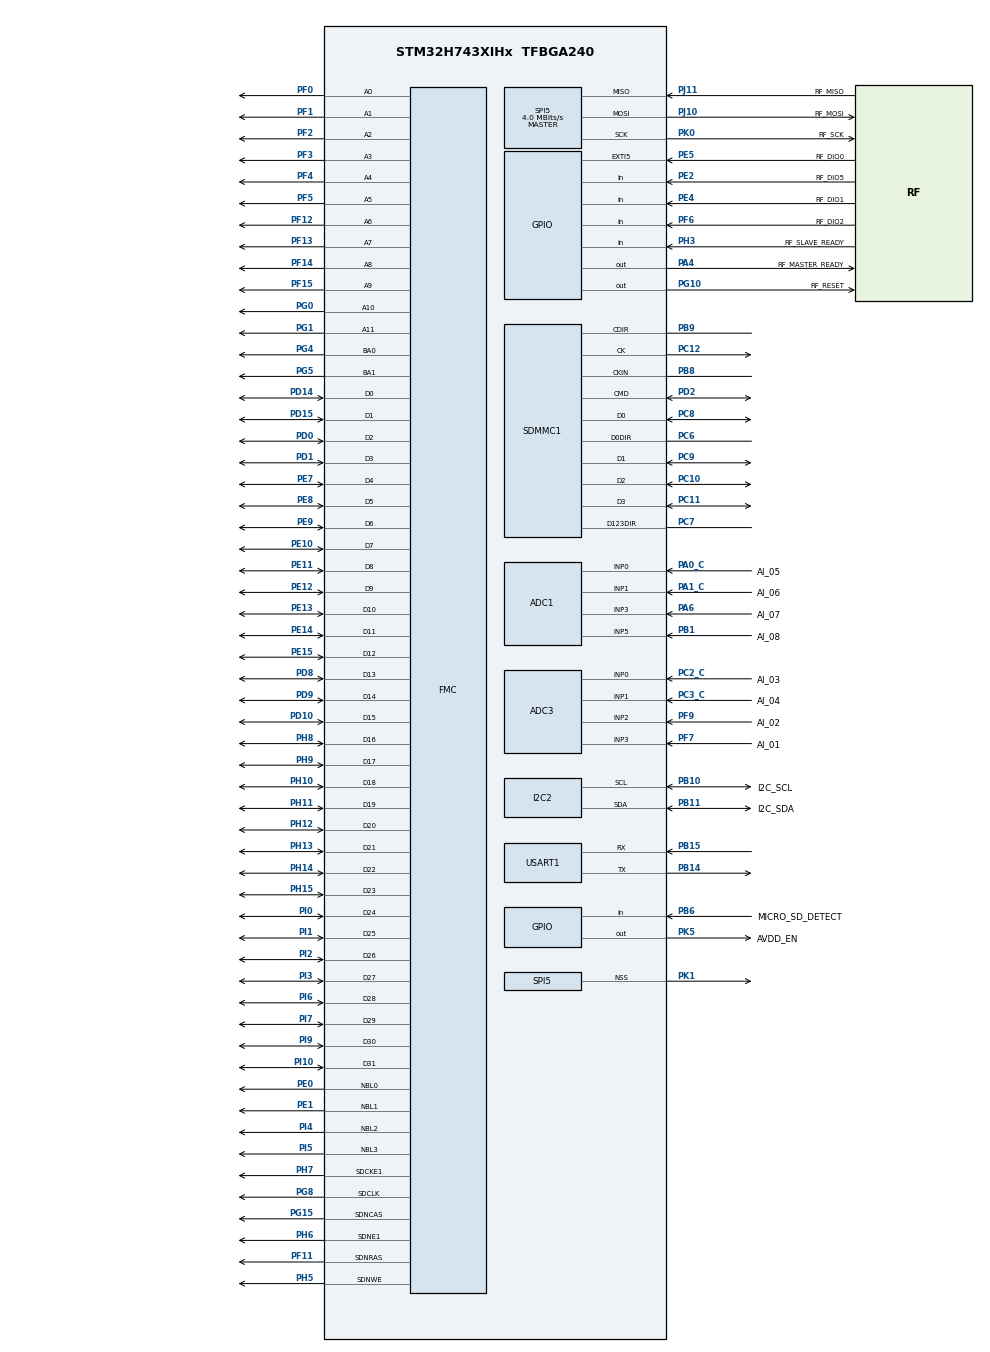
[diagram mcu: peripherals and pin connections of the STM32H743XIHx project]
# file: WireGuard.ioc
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ADC1.Channel-0\#ChannelRegularConversion=ADC_CHANNEL_0
ADC1.ClockPrescaler=ADC_CLOCK_ASYNC_DIV2
ADC1.ContinuousConvMode=ENABLE
ADC1.NbrOfConversionFlag=1
ADC1.OffsetNumber-0\#ChannelRegularConversion=ADC_OFFSET_NONE
ADC1.Rank-0\#ChannelRegularConversion=1
ADC1.SamplingTime-0\#ChannelRegularConversion=ADC_SAMPLETIME_1CYCLE_5
ADC1.master=1
ADC3.Channel-0\#ChannelRegularConversion=ADC_CHANNEL_0
ADC3.ContinuousConvMode=ENABLE
ADC3.LowPowerAutoWait=DISABLE
ADC3.NbrOfConversionFlag=1
ADC3.OffsetNumber-0\#ChannelRegularConversion=ADC_OFFSET_NONE
ADC3.Rank-0\#ChannelRegularConversion=1
ADC3.SamplingTime-0\#ChannelRegularConversion=ADC_SAMPLETIME_1CYCLE_5
FATFS.BSP.number=1
FATFS0.BSP.STBoard=false
FATFS0.BSP.api=Unknown
FATFS0.BSP.i2caddr=0
FATFS0.BSP.instance=PB6
FATFS0.BSP.ip=GPIO
FATFS0.BSP.mode=Input
FATFS0.BSP.name=Detect_SDIO
FATFS0.BSP.solution=PB6
FMC.CASLatency1=FMC_SDRAM_CAS_LATENCY_3
FMC.ColumnBitsNumber1=FMC_SDRAM_COLUMN_BITS_NUM_9
FMC.ExitSelfRefreshDelay1=7
FMC.LoadToActiveDelay1=2
FMC.RCDDelay1=2
FMC.RPDelay1=2
FMC.RPDelay2=2
FMC.ReadBurst1=FMC_SDRAM_RBURST_ENABLE
FMC.ReadBurst2=FMC_SDRAM_RBURST_ENABLE
FMC.RowCycleDelay1=7
FMC.RowCycleDelay2=7
FMC.SDClockPeriod1=FMC_SDRAM_CLOCK_PERIOD_2
FMC.SelfRefreshTime1=4
FMC.WriteRecoveryTime1=4
FREERTOS.HEAP_NUMBER=4
FREERTOS.Tasks01=defaultTask,0,512,MAIN_taskEntry,As weak,NULL,Dynamic,NULL,NULL
FREERTOS.Timers01=timerSystemMonitor,SYSTEM_montiorCallback,osTimerPeriodic,As weak,NULL,Dynamic,NULL
FREERTOS.configCHECK_FOR_STACK_OVERFLOW=1
FREERTOS.configMINIMAL_STACK_SIZE=256
FREERTOS.configTOTAL_HEAP_SIZE=32768
FREERTOS.configUSE_TIMERS=1
I2C2.Timing=0x10909CEC
Mcu.Family=STM32H7
Mcu.Name=STM32H743XIHx
Mcu.Package=TFBGA240
NVIC.ADC3_IRQn=true\:5\:0\:false\:false\:true\:true\:true\:true
NVIC.ADC_IRQn=true\:5\:0\:false\:false\:true\:true\:true\:true
NVIC.EXTI9_5_IRQn=true\:5\:0\:false\:false\:true\:true\:true\:true
NVIC.PriorityGroup=NVIC_PRIORITYGROUP_4
NVIC.SPI5_IRQn=true\:5\:0\:false\:false\:true\:true\:true\:true
NVIC.TIM1_UP_IRQn=true\:0\:0\:false\:false\:true\:false\:false\:false
NVIC.TimeBase=TIM1_UP_IRQn
NVIC.TimeBaseIP=TIM1
PA0_C.GPIO_Label=AI_05
PA0_C.Signal=ADCx_INP0
PA13\ (JTMS/SWDIO).Mode=JTAG_5_pins
PA13\ (JTMS/SWDIO).Signal=SYS_JTMS-SWDIO
PA14\ (JTCK/SWCLK).Mode=JTAG_5_pins
PA14\ (JTCK/SWCLK).Signal=SYS_JTCK-SWCLK
PA15\ (JTDI).Mode=JTAG_5_pins
PA15\ (JTDI).Signal=SYS_JTDI
PA1_C.GPIO_Label=AI_06
PA1_C.Signal=ADCx_INP1
PA4.GPIO_Label=RF_MASTER_READY
PA4.GPIO_PuPd=GPIO_PULLUP
PA4.GPIO_Speed=GPIO_SPEED_FREQ_VERY_HIGH
PA4.Signal=GPIO_Output
PA6.GPIO_Label=AI_07
PA6.Signal=ADCx_INP3
PB1.GPIO_Label=AI_08
PB1.Signal=ADCx_INP5
PB10.GPIO_Label=I2C_SCL
PB10.GPIO_PuPd=GPIO_PULLUP
PB10.Mode=I2C
PB10.Signal=I2C2_SCL
PB11.GPIO_Label=I2C_SDA
PB11.GPIO_PuPd=GPIO_PULLUP
PB11.Mode=I2C
PB11.Signal=I2C2_SDA
PB14.Mode=Asynchronous
PB14.Signal=USART1_TX
PB15.Mode=Asynchronous
PB15.Signal=USART1_RX
PB3\ (JTDO/TRACESWO).Mode=JTAG_5_pins
PB3\ (JTDO/TRACESWO).Signal=SYS_JTDO-SWO
PB4\ (NJTRST).Mode=JTAG_5_pins
PB4\ (NJTRST).Signal=SYS_JTRST
PB6.GPIO_Label=MICRO_SD_DETECT
PB6.Signal=GPIO_Input
PB8.Mode=SD_4_bits_Wide_bus_dir_voltage_converter
PB8.Signal=SDMMC1_CKIN
PB9.Mode=SD_4_bits_Wide_bus_dir_voltage_converter
PB9.Signal=SDMMC1_CDIR
PC10.Mode=SD_4_bits_Wide_bus_dir_voltage_converter
PC10.Signal=SDMMC1_D2
PC11.Mode=SD_4_bits_Wide_bus_dir_voltage_converter
PC11.Signal=SDMMC1_D3
PC12.Mode=SD_4_bits_Wide_bus_dir_voltage_converter
PC12.Signal=SDMMC1_CK
PC14-OSC32_IN\ (OSC32_IN).Mode=LSE-External-Oscillator
PC14-OSC32_IN\ (OSC32_IN).Signal=RCC_OSC32_IN
PC15-OSC32_OUT\ (OSC32_OUT).Mode=LSE-External-Oscillator
PC15-OSC32_OUT\ (OSC32_OUT).Signal=RCC_OSC32_OUT
PC2_C.GPIO_Label=AI_03
PC2_C.Mode=IN0-Single-Ended
PC2_C.Signal=ADC3_INP0
PC3_C.GPIO_Label=AI_04
PC3_C.Mode=IN1-Single-Ended
PC3_C.Signal=ADC3_INP1
PC6.Mode=SD_4_bits_Wide_bus_dir_voltage_converter
PC6.Signal=SDMMC1_D0DIR
PC7.Mode=SD_4_bits_Wide_bus_dir_voltage_converter
PC7.Signal=SDMMC1_D123DIR
PC8.Mode=SD_4_bits_Wide_bus_dir_voltage_converter
PC8.Signal=SDMMC1_D0
PC9.Mode=SD_4_bits_Wide_bus_dir_voltage_converter
PC9.Signal=SDMMC1_D1
PD0.Signal=FMC_D2_DA2
PD1.Signal=FMC_D3_DA3
PD10.Signal=FMC_D15_DA15
PD14.Signal=FMC_D0_DA0
PD15.Signal=FMC_D1_DA1
PD2.Mode=SD_4_bits_Wide_bus_dir_voltage_converter
PD2.Signal=SDMMC1_CMD
PD8.Signal=FMC_D13_DA13
PD9.Signal=FMC_D14_DA14
PE0.Signal=FMC_NBL0
PE1.Signal=FMC_NBL1
PE10.Signal=FMC_D7_DA7
PE11.Signal=FMC_D8_DA8
PE12.Signal=FMC_D9_DA9
PE13.Signal=FMC_D10_DA10
PE14.Signal=FMC_D11_DA11
PE15.Signal=FMC_D12_DA12
PE2.GPIO_Label=RF_DIO5
PE2.Signal=GPIO_Input
PE4.GPIO_Label=RF_DIO1
PE4.Signal=GPIO_Input
PE5.GPIO_Label=RF_DIO0
PE5.Signal=GPXTI5
PE7.Signal=FMC_D4_DA4
PE8.Signal=FMC_D5_DA5
PE9.Signal=FMC_D6_DA6
PF0.Signal=FMC_A0
PF1.Signal=FMC_A1
PF11.Signal=FMC_SDNRAS
PF12.Signal=FMC_A6
PF13.Signal=FMC_A7
PF14.Signal=FMC_A8
PF15.Signal=FMC_A9
PF2.Signal=FMC_A2
PF3.Signal=FMC_A3
PF4.Signal=FMC_A4
PF5.Signal=FMC_A5
PF6.GPIO_Label=RF_DIO2
PF6.Signal=GPIO_Input
PF7.GPIO_Label=AI_01
PF7.Mode=IN3-Single-Ended
PF7.Signal=ADC3_INP3
PF9.GPIO_Label=AI_02
PF9.Mode=IN2-Single-Ended
PF9.Signal=ADC3_INP2
PG0.Signal=FMC_A10
PG1.Signal=FMC_A11
PG10.GPIO_Label=RF_RESET
PG10.GPIO_ModeDefaultOutputPP=GPIO_MODE_OUTPUT_OD
PG10.GPIO_PuPd=GPIO_NOPULL
PG10.PinState=GPIO_PIN_RESET
PG10.Signal=GPIO_Output
PG15.Signal=FMC_SDNCAS
PG4.Signal=FMC_A14_BA0
PG5.Signal=FMC_A15_BA1
PG8.Signal=FMC_SDCLK
PH0-OSC_IN\ (PH0).Signal=RCC_OSC_IN
PH1-OSC_OUT\ (PH1).Signal=RCC_OSC_OUT
PH10.Signal=FMC_D18
PH11.Signal=FMC_D19
PH12.Signal=FMC_D20
PH13.Signal=FMC_D21
PH14.Signal=FMC_D22
PH15.Signal=FMC_D23
PH3.GPIO_Label=RF_SLAVE_READY
PH3.GPIO_PuPd=GPIO_PULLUP
PH3.Signal=GPIO_Input
PH5.Signal=FMC_SDNWE
PH6.Mode=SdramChipSelect2_1
PH6.Signal=FMC_SDNE1
PH7.Mode=SdramChipSelect2_1
PH7.Signal=FMC_SDCKE1
PH8.Signal=FMC_D16
PH9.Signal=FMC_D17
PI0.Signal=FMC_D24
PI1.Signal=FMC_D25
PI10.Signal=FMC_D31
PI2.Signal=FMC_D26
PI3.Signal=FMC_D27
PI4.Signal=FMC_NBL2
PI5.Signal=FMC_NBL3
PI6.Signal=FMC_D28
PI7.Signal=FMC_D29
PI9.Signal=FMC_D30
PJ10.GPIO_Label=RF_MOSI
PJ10.Mode=Full_Duplex_Master
PJ10.Signal=SPI5_MOSI
PJ11.GPIO_Label=RF_MISO
PJ11.Mode=Full_Duplex_Master
PJ11.Signal=SPI5_MISO
PK0.GPIO_Label=RF_SCK
PK0.Mode=Full_Duplex_Master
PK0.Signal=SPI5_SCK
PK1.Mode=NSS_Signal_Hard_Output
PK1.Signal=SPI5_NSS
PK5.GPIO_Label=AVDD_EN
PK5.GPIO_PuPd=GPIO_PULLDOWN
PK5.Signal=GPIO_Output
ProjectManager.HeapSize=0x200
ProjectManager.StackSize=0x400
ProjectManager.TargetToolchain=EWARM V8
RCC.ADCCLockSelection=RCC_ADCCLKSOURCE_CLKP
RCC.ADCFreq_Value=64000000
RCC.APB1Freq_Value=80000000
RCC.APB2Freq_Value=20000000
RCC.APB3Freq_Value=80000000
RCC.APB4Freq_Value=80000000
RCC.CortexFreq_Value=80000000
RCC.D2PPRE2=RCC_APB2_DIV4
RCC.DIVM1=4
RCC.DIVM2=4
RCC.DIVN1=10
RCC.DIVN2=10
RCC.DIVP2=1
RCC.HCLKFreq_Value=80000000
RCC.HSE_VALUE=25000000
RCC.PWR_Regulator_Voltage_Scale=PWR_REGULATOR_VOLTAGE_SCALE1
RCC.SYSCLKFreq_VALUE=80000000
RCC.SYSCLKSource=RCC_SYSCLKSOURCE_PLLCLK
RCC.Spi45ClockSelection=RCC_SPI45CLKSOURCE_HSI
RCC.USBFreq_Value=80000000
SH.ADCx_INP0.0=ADC1_INP0,IN0-Single-Ended
SH.ADCx_INP1.0=ADC1_INP1,IN1-Single-Ended
SH.ADCx_INP3.0=ADC1_INP3,IN3-Single-Ended
SH.ADCx_INP5.0=ADC1_INP5,IN5-Single-Ended
SH.FMC_A0.0=FMC_A0,12b-sda1
SH.FMC_A1.0=FMC_A1,12b-sda1
SH.FMC_A10.0=FMC_A10,12b-sda1
SH.FMC_A11.0=FMC_A11,12b-sda1
SH.FMC_A14_BA0.0=FMC_BA0,FourSdramBanks1
SH.FMC_A15_BA1.0=FMC_BA1,FourSdramBanks1
SH.FMC_A2.0=FMC_A2,12b-sda1
SH.FMC_A3.0=FMC_A3,12b-sda1
SH.FMC_A4.0=FMC_A4,12b-sda1
SH.FMC_A5.0=FMC_A5,12b-sda1
SH.FMC_A6.0=FMC_A6,12b-sda1
SH.FMC_A7.0=FMC_A7,12b-sda1
SH.FMC_A8.0=FMC_A8,12b-sda1
SH.FMC_A9.0=FMC_A9,12b-sda1
SH.FMC_D0_DA0.0=FMC_D0,sd-32b-d1
SH.FMC_D10_DA10.0=FMC_D10,sd-32b-d1
SH.FMC_D11_DA11.0=FMC_D11,sd-32b-d1
SH.FMC_D12_DA12.0=FMC_D12,sd-32b-d1
SH.FMC_D13_DA13.0=FMC_D13,sd-32b-d1
SH.FMC_D14_DA14.0=FMC_D14,sd-32b-d1
SH.FMC_D15_DA15.0=FMC_D15,sd-32b-d1
SH.FMC_D16.0=FMC_D16,sd-32b-d1
SH.FMC_D17.0=FMC_D17,sd-32b-d1
SH.FMC_D18.0=FMC_D18,sd-32b-d1
SH.FMC_D19.0=FMC_D19,sd-32b-d1
SH.FMC_D1_DA1.0=FMC_D1,sd-32b-d1
SH.FMC_D20.0=FMC_D20,sd-32b-d1
SH.FMC_D21.0=FMC_D21,sd-32b-d1
SH.FMC_D22.0=FMC_D22,sd-32b-d1
SH.FMC_D23.0=FMC_D23,sd-32b-d1
SH.FMC_D24.0=FMC_D24,sd-32b-d1
SH.FMC_D25.0=FMC_D25,sd-32b-d1
SH.FMC_D26.0=FMC_D26,sd-32b-d1
SH.FMC_D27.0=FMC_D27,sd-32b-d1
SH.FMC_D28.0=FMC_D28,sd-32b-d1
SH.FMC_D29.0=FMC_D29,sd-32b-d1
SH.FMC_D2_DA2.0=FMC_D2,sd-32b-d1
SH.FMC_D30.0=FMC_D30,sd-32b-d1
SH.FMC_D31.0=FMC_D31,sd-32b-d1
SH.FMC_D3_DA3.0=FMC_D3,sd-32b-d1
SH.FMC_D4_DA4.0=FMC_D4,sd-32b-d1
SH.FMC_D5_DA5.0=FMC_D5,sd-32b-d1
SH.FMC_D6_DA6.0=FMC_D6,sd-32b-d1
SH.FMC_D7_DA7.0=FMC_D7,sd-32b-d1
SH.FMC_D8_DA8.0=FMC_D8,sd-32b-d1
SH.FMC_D9_DA9.0=FMC_D9,sd-32b-d1
SH.FMC_NBL0.0=FMC_NBL0,Sd4ByteEnable1
SH.FMC_NBL1.0=FMC_NBL1,Sd4ByteEnable1
SH.FMC_NBL2.0=FMC_NBL2,Sd4ByteEnable1
SH.FMC_NBL3.0=FMC_NBL3,Sd4ByteEnable1
SH.FMC_SDCLK.0=FMC_SDCLK,12b-sda1
SH.FMC_SDNCAS.0=FMC_SDNCAS,12b-sda1
SH.FMC_SDNRAS.0=FMC_SDNRAS,12b-sda1
SH.FMC_SDNWE.0=FMC_SDNWE,12b-sda1
SPI5.BaudRatePrescaler=SPI_BAUDRATEPRESCALER_16
SPI5.CLKPhase=SPI_PHASE_1EDGE
SPI5.CLKPolarity=SPI_POLARITY_LOW
SPI5.CalculateBaudRate=4.0 MBits/s
SPI5.DataSize=SPI_DATASIZE_8BIT
SPI5.Direction=SPI_DIRECTION_2LINES
SPI5.Mode=SPI_MODE_MASTER
SPI5.NSSPMode=SPI_NSS_PULSE_ENABLE
SPI5.RxCRCInitializationPattern=SPI_CRC_INITIALIZATION_ALL_ZERO_PATTERN
SPI5.TxCRCInitializationPattern=SPI_CRC_INITIALIZATION_ALL_ZERO_PATTERN
SPI5.VirtualNSS=VM_NSSHARD
SPI5.VirtualType=VM_MASTER
USART1.VirtualMode-Asynchronous=VM_ASYNC
VP_FATFS_VS_SDIO.Mode=SDIO
VP_FREERTOS_VS_CMSIS_V1.Mode=CMSIS_V1
VP_RTC_VS_RTC_Activate.Mode=RTC_Enabled
VP_SYS_VS_tim1.Mode=TIM1
board=custom

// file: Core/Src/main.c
/* USER CODE BEGIN Header */
/**
  ******************************************************************************
  * @file           : main.c
  * @brief          : Main program body
  ******************************************************************************
  * @attention
  *
  * <h2><center>&copy; Copyright (c) 2019 STMicroelectronics.
  * All rights reserved.</center></h2>
  *
  * This software component is licensed by ST under Ultimate Liberty license
  * SLA0044, the "License"; You may not use this file except in compliance with
  * the License. You may obtain a copy of the License at:
  *                             www.st.com/SLA0044
  *
  ******************************************************************************
  */
/* USER CODE END Header */

#include "main.h"
#include "cmsis_os.h"
#include "fatfs.h"

/* USER CODE BEGIN Includes */
#include "sdram.h"
#include "adc.h"
#include "rf.h"
#include "i2c.h"
#include "wireguard.h"
/* USER CODE END Includes */

ADC_HandleTypeDef hadc1;
ADC_HandleTypeDef hadc3;

I2C_HandleTypeDef hi2c2;

RTC_HandleTypeDef hrtc;

SD_HandleTypeDef hsd1;

SPI_HandleTypeDef hspi5;

UART_HandleTypeDef huart1;

SDRAM_HandleTypeDef hsdram1;

osThreadId defaultTaskHandle;
osTimerId timerSystemMonitorHandle;
/* USER CODE BEGIN PV */
/* Private variables ---------------------------------------------------------*/
ADC_HandleTypeDef*  adcList[] = {&hadc1, &hadc3};

/* USER CODE END PV */

void SystemClock_Config(void);
static void MX_GPIO_Init(void);
static void MX_ADC1_Init(void);
static void MX_ADC3_Init(void);
static void MX_FMC_Init(void);
static void MX_SDMMC1_SD_Init(void);
static void MX_USART1_UART_Init(void);
static void MX_SPI5_Init(void);
static void MX_RTC_Init(void);
static void MX_I2C2_Init(void);
void MAIN_taskEntry(void const * argument);
void SYSTEM_montiorCallback(void const * argument);

/* USER CODE BEGIN PFP */
/* Private function prototypes -----------------------------------------------*/

/* USER CODE END PFP */

int main(void)
{

  /* MCU Configuration--------------------------------------------------------*/

  /* Reset of all peripherals, Initializes the Flash interface and the Systick. */
  HAL_Init();

  /* Configure the system clock */
  SystemClock_Config();

  /* Initialize all configured peripherals */
  MX_GPIO_Init();
  MX_ADC1_Init();
  MX_ADC3_Init();
  MX_FMC_Init();
  MX_SDMMC1_SD_Init();
  MX_USART1_UART_Init();
  MX_SPI5_Init();
  MX_RTC_Init();
  MX_I2C2_Init();
  /* USER CODE BEGIN 2 */
  ADC_init(adcList, 2);
  SDRAM_init(&hsdram1);
  RF_init(&hspi5);
  I2C_init(&hi2c2);

  /* USER CODE END 2 */

  /* Create the timer(s) */
  /* definition and creation of timerSystemMonitor */
  osTimerDef(timerSystemMonitor, SYSTEM_montiorCallback);
  timerSystemMonitorHandle = osTimerCreate(osTimer(timerSystemMonitor), osTimerPeriodic, NULL);

  /* Create the thread(s) */
  /* definition and creation of defaultTask */
  osThreadDef(defaultTask, MAIN_taskEntry, osPriorityNormal, 0, 512);
  defaultTaskHandle = osThreadCreate(osThread(defaultTask), NULL);

  /* Start scheduler */
  osKernelStart();

  /* We should never get here as control is now taken by the scheduler */

  /* Infinite loop */
  while (1)
  {

  }
}

void SystemClock_Config(void)
{
  RCC_OscInitTypeDef RCC_OscInitStruct = {0};
  RCC_ClkInitTypeDef RCC_ClkInitStruct = {0};
  RCC_PeriphCLKInitTypeDef PeriphClkInitStruct = {0};

  /** Supply configuration update enable
  */
  MODIFY_REG(PWR->CR3, PWR_CR3_SCUEN, 0);
  /** Configure the main internal regulator output voltage
  */
  __HAL_PWR_VOLTAGESCALING_CONFIG(PWR_REGULATOR_VOLTAGE_SCALE1);

  while ((PWR->D3CR & (PWR_D3CR_VOSRDY)) != PWR_D3CR_VOSRDY)
  {

  }
  /** Initializes the CPU, AHB and APB busses clocks
  */
  RCC_OscInitStruct.OscillatorType = RCC_OSCILLATORTYPE_HSI|RCC_OSCILLATORTYPE_LSI;
  RCC_OscInitStruct.HSIState = RCC_HSI_DIV1;
  RCC_OscInitStruct.HSICalibrationValue = RCC_HSICALIBRATION_DEFAULT;
  RCC_OscInitStruct.LSIState = RCC_LSI_ON;
  RCC_OscInitStruct.PLL.PLLState = RCC_PLL_ON;
  RCC_OscInitStruct.PLL.PLLSource = RCC_PLLSOURCE_HSI;
  RCC_OscInitStruct.PLL.PLLM = 4;
  RCC_OscInitStruct.PLL.PLLN = 10;
  RCC_OscInitStruct.PLL.PLLP = 2;
  RCC_OscInitStruct.PLL.PLLQ = 2;
  RCC_OscInitStruct.PLL.PLLR = 2;
  RCC_OscInitStruct.PLL.PLLRGE = RCC_PLL1VCIRANGE_3;
  RCC_OscInitStruct.PLL.PLLVCOSEL = RCC_PLL1VCOMEDIUM;
  RCC_OscInitStruct.PLL.PLLFRACN = 0;
  if (HAL_RCC_OscConfig(&RCC_OscInitStruct) != HAL_OK)
  {
    Error_Handler();
  }
  /** Initializes the CPU, AHB and APB busses clocks
  */
  RCC_ClkInitStruct.ClockType = RCC_CLOCKTYPE_HCLK|RCC_CLOCKTYPE_SYSCLK
                              |RCC_CLOCKTYPE_PCLK1|RCC_CLOCKTYPE_PCLK2
                              |RCC_CLOCKTYPE_D3PCLK1|RCC_CLOCKTYPE_D1PCLK1;
  RCC_ClkInitStruct.SYSCLKSource = RCC_SYSCLKSOURCE_PLLCLK;
  RCC_ClkInitStruct.SYSCLKDivider = RCC_SYSCLK_DIV1;
  RCC_ClkInitStruct.AHBCLKDivider = RCC_HCLK_DIV1;
  RCC_ClkInitStruct.APB3CLKDivider = RCC_APB3_DIV1;
  RCC_ClkInitStruct.APB1CLKDivider = RCC_APB1_DIV1;
  RCC_ClkInitStruct.APB2CLKDivider = RCC_APB2_DIV4;
  RCC_ClkInitStruct.APB4CLKDivider = RCC_APB4_DIV1;

  if (HAL_RCC_ClockConfig(&RCC_ClkInitStruct, FLASH_LATENCY_1) != HAL_OK)
  {
    Error_Handler();
  }
  PeriphClkInitStruct.PeriphClockSelection = RCC_PERIPHCLK_RTC|RCC_PERIPHCLK_USART1
                              |RCC_PERIPHCLK_SPI5|RCC_PERIPHCLK_SDMMC
                              |RCC_PERIPHCLK_I2C2|RCC_PERIPHCLK_ADC
                              |RCC_PERIPHCLK_FMC|RCC_PERIPHCLK_CKPER;
  PeriphClkInitStruct.FmcClockSelection = RCC_FMCCLKSOURCE_D1HCLK;
  PeriphClkInitStruct.SdmmcClockSelection = RCC_SDMMCCLKSOURCE_PLL;
  PeriphClkInitStruct.CkperClockSelection = RCC_CLKPSOURCE_HSI;
  PeriphClkInitStruct.Spi45ClockSelection = RCC_SPI45CLKSOURCE_HSI;
  PeriphClkInitStruct.Usart16ClockSelection = RCC_USART16CLKSOURCE_D2PCLK2;
  PeriphClkInitStruct.I2c123ClockSelection = RCC_I2C123CLKSOURCE_D2PCLK1;
  PeriphClkInitStruct.AdcClockSelection = RCC_ADCCLKSOURCE_CLKP;
  PeriphClkInitStruct.RTCClockSelection = RCC_RTCCLKSOURCE_LSI;
  if (HAL_RCCEx_PeriphCLKConfig(&PeriphClkInitStruct) != HAL_OK)
  {
    Error_Handler();
  }
}

static void MX_ADC1_Init(void)
{

  ADC_MultiModeTypeDef multimode = {0};
  ADC_ChannelConfTypeDef sConfig = {0};

  /** Common config
  */
  hadc1.Instance = ADC1;
  hadc1.Init.ClockPrescaler = ADC_CLOCK_ASYNC_DIV2;
  hadc1.Init.Resolution = ADC_RESOLUTION_16B;
  hadc1.Init.ScanConvMode = ADC_SCAN_DISABLE;
  hadc1.Init.EOCSelection = ADC_EOC_SINGLE_CONV;
  hadc1.Init.LowPowerAutoWait = DISABLE;
  hadc1.Init.ContinuousConvMode = ENABLE;
  hadc1.Init.NbrOfConversion = 1;
  hadc1.Init.DiscontinuousConvMode = DISABLE;
  hadc1.Init.ExternalTrigConv = ADC_SOFTWARE_START;
  hadc1.Init.ExternalTrigConvEdge = ADC_EXTERNALTRIGCONVEDGE_NONE;
  hadc1.Init.ConversionDataManagement = ADC_CONVERSIONDATA_DR;
  hadc1.Init.Overrun = ADC_OVR_DATA_PRESERVED;
  hadc1.Init.LeftBitShift = ADC_LEFTBITSHIFT_NONE;
  hadc1.Init.BoostMode = DISABLE;
  hadc1.Init.OversamplingMode = DISABLE;
  if (HAL_ADC_Init(&hadc1) != HAL_OK)
  {
    Error_Handler();
  }
  /** Configure the ADC multi-mode
  */
  multimode.Mode = ADC_MODE_INDEPENDENT;
  if (HAL_ADCEx_MultiModeConfigChannel(&hadc1, &multimode) != HAL_OK)
  {
    Error_Handler();
  }
  /** Configure Regular Channel
  */
  sConfig.Channel = ADC_CHANNEL_0;
  sConfig.Rank = ADC_REGULAR_RANK_1;
  sConfig.SamplingTime = ADC_SAMPLETIME_1CYCLE_5;
  sConfig.SingleDiff = ADC_SINGLE_ENDED;
  sConfig.OffsetNumber = ADC_OFFSET_NONE;
  sConfig.Offset = 0;
  if (HAL_ADC_ConfigChannel(&hadc1, &sConfig) != HAL_OK)
  {
    Error_Handler();
  }

}

static void MX_ADC3_Init(void)
{

  ADC_ChannelConfTypeDef sConfig = {0};

  /** Common config
  */
  hadc3.Instance = ADC3;
  hadc3.Init.ClockPrescaler = ADC_CLOCK_ASYNC_DIV2;
  hadc3.Init.Resolution = ADC_RESOLUTION_16B;
  hadc3.Init.ScanConvMode = ADC_SCAN_DISABLE;
  hadc3.Init.EOCSelection = ADC_EOC_SINGLE_CONV;
  hadc3.Init.LowPowerAutoWait = DISABLE;
  hadc3.Init.ContinuousConvMode = ENABLE;
  hadc3.Init.NbrOfConversion = 1;
  hadc3.Init.DiscontinuousConvMode = DISABLE;
  hadc3.Init.ExternalTrigConv = ADC_SOFTWARE_START;
  hadc3.Init.ExternalTrigConvEdge = ADC_EXTERNALTRIGCONVEDGE_NONE;
  hadc3.Init.ConversionDataManagement = ADC_CONVERSIONDATA_DR;
  hadc3.Init.Overrun = ADC_OVR_DATA_PRESERVED;
  hadc3.Init.LeftBitShift = ADC_LEFTBITSHIFT_NONE;
  hadc3.Init.BoostMode = DISABLE;
  hadc3.Init.OversamplingMode = DISABLE;
  if (HAL_ADC_Init(&hadc3) != HAL_OK)
  {
    Error_Handler();
  }
  /** Configure Regular Channel
  */
  sConfig.Channel = ADC_CHANNEL_0;
  sConfig.Rank = ADC_REGULAR_RANK_1;
  sConfig.SamplingTime = ADC_SAMPLETIME_1CYCLE_5;
  sConfig.SingleDiff = ADC_SINGLE_ENDED;
  sConfig.OffsetNumber = ADC_OFFSET_NONE;
  sConfig.Offset = 0;
  if (HAL_ADC_ConfigChannel(&hadc3, &sConfig) != HAL_OK)
  {
    Error_Handler();
  }

}

static void MX_I2C2_Init(void)
{

  hi2c2.Instance = I2C2;
  hi2c2.Init.Timing = 0x10909CEC;
  hi2c2.Init.OwnAddress1 = 0;
  hi2c2.Init.AddressingMode = I2C_ADDRESSINGMODE_7BIT;
  hi2c2.Init.DualAddressMode = I2C_DUALADDRESS_DISABLE;
  hi2c2.Init.OwnAddress2 = 0;
  hi2c2.Init.OwnAddress2Masks = I2C_OA2_NOMASK;
  hi2c2.Init.GeneralCallMode = I2C_GENERALCALL_DISABLE;
  hi2c2.Init.NoStretchMode = I2C_NOSTRETCH_DISABLE;
  if (HAL_I2C_Init(&hi2c2) != HAL_OK)
  {
    Error_Handler();
  }
  /** Configure Analogue filter
  */
  if (HAL_I2CEx_ConfigAnalogFilter(&hi2c2, I2C_ANALOGFILTER_ENABLE) != HAL_OK)
  {
    Error_Handler();
  }
  /** Configure Digital filter
  */
  if (HAL_I2CEx_ConfigDigitalFilter(&hi2c2, 0) != HAL_OK)
  {
    Error_Handler();
  }

}

static void MX_RTC_Init(void)
{

  /** Initialize RTC Only
  */
  hrtc.Instance = RTC;
  hrtc.Init.HourFormat = RTC_HOURFORMAT_24;
  hrtc.Init.AsynchPrediv = 127;
  hrtc.Init.SynchPrediv = 255;
  hrtc.Init.OutPut = RTC_OUTPUT_DISABLE;
  hrtc.Init.OutPutPolarity = RTC_OUTPUT_POLARITY_HIGH;
  hrtc.Init.OutPutType = RTC_OUTPUT_TYPE_OPENDRAIN;
  hrtc.Init.OutPutRemap = RTC_OUTPUT_REMAP_NONE;
  if (HAL_RTC_Init(&hrtc) != HAL_OK)
  {
    Error_Handler();
  }

}

static void MX_SDMMC1_SD_Init(void)
{

  hsd1.Instance = SDMMC1;
  hsd1.Init.ClockEdge = SDMMC_CLOCK_EDGE_RISING;
  hsd1.Init.ClockPowerSave = SDMMC_CLOCK_POWER_SAVE_DISABLE;
  hsd1.Init.BusWide = SDMMC_BUS_WIDE_4B;
  hsd1.Init.HardwareFlowControl = SDMMC_HARDWARE_FLOW_CONTROL_DISABLE;
  hsd1.Init.ClockDiv = 0;

}

static void MX_SPI5_Init(void)
{

  /* SPI5 parameter configuration*/
  hspi5.Instance = SPI5;
  hspi5.Init.Mode = SPI_MODE_MASTER;
  hspi5.Init.Direction = SPI_DIRECTION_2LINES;
  hspi5.Init.DataSize = SPI_DATASIZE_8BIT;
  hspi5.Init.CLKPolarity = SPI_POLARITY_LOW;
  hspi5.Init.CLKPhase = SPI_PHASE_1EDGE;
  hspi5.Init.NSS = SPI_NSS_HARD_OUTPUT;
  hspi5.Init.BaudRatePrescaler = SPI_BAUDRATEPRESCALER_16;
  hspi5.Init.FirstBit = SPI_FIRSTBIT_MSB;
  hspi5.Init.TIMode = SPI_TIMODE_DISABLE;
  hspi5.Init.CRCCalculation = SPI_CRCCALCULATION_DISABLE;
  hspi5.Init.CRCPolynomial = 7;
  hspi5.Init.NSSPMode = SPI_NSS_PULSE_ENABLE;
  hspi5.Init.NSSPolarity = SPI_NSS_POLARITY_LOW;
  hspi5.Init.FifoThreshold = SPI_FIFO_THRESHOLD_01DATA;
  hspi5.Init.TxCRCInitializationPattern = SPI_CRC_INITIALIZATION_ALL_ZERO_PATTERN;
  hspi5.Init.RxCRCInitializationPattern = SPI_CRC_INITIALIZATION_ALL_ZERO_PATTERN;
  hspi5.Init.MasterSSIdleness = SPI_MASTER_SS_IDLENESS_00CYCLE;
  hspi5.Init.MasterInterDataIdleness = SPI_MASTER_INTERDATA_IDLENESS_00CYCLE;
  hspi5.Init.MasterReceiverAutoSusp = SPI_MASTER_RX_AUTOSUSP_DISABLE;
  hspi5.Init.MasterKeepIOState = SPI_MASTER_KEEP_IO_STATE_DISABLE;
  hspi5.Init.IOSwap = SPI_IO_SWAP_DISABLE;
  if (HAL_SPI_Init(&hspi5) != HAL_OK)
  {
    Error_Handler();
  }

}

static void MX_USART1_UART_Init(void)
{

  huart1.Instance = USART1;
  huart1.Init.BaudRate = 115200;
  huart1.Init.WordLength = UART_WORDLENGTH_8B;
  huart1.Init.StopBits = UART_STOPBITS_1;
  huart1.Init.Parity = UART_PARITY_NONE;
  huart1.Init.Mode = UART_MODE_TX_RX;
  huart1.Init.HwFlowCtl = UART_HWCONTROL_NONE;
  huart1.Init.OverSampling = UART_OVERSAMPLING_16;
  huart1.Init.OneBitSampling = UART_ONE_BIT_SAMPLE_DISABLE;
  huart1.Init.Prescaler = UART_PRESCALER_DIV1;
  huart1.Init.FIFOMode = UART_FIFOMODE_DISABLE;
  huart1.Init.TXFIFOThreshold = UART_TXFIFO_THRESHOLD_1_8;
  huart1.Init.RXFIFOThreshold = UART_RXFIFO_THRESHOLD_1_8;
  huart1.AdvancedInit.AdvFeatureInit = UART_ADVFEATURE_NO_INIT;
  if (HAL_UART_Init(&huart1) != HAL_OK)
  {
    Error_Handler();
  }

}

/* FMC initialization function */
static void MX_FMC_Init(void)
{
  FMC_SDRAM_TimingTypeDef SdramTiming;

  /** Perform the SDRAM1 memory initialization sequence
  */
  hsdram1.Instance = FMC_SDRAM_DEVICE;
  /* hsdram1.Init */
  hsdram1.Init.SDBank = FMC_SDRAM_BANK2;
  hsdram1.Init.ColumnBitsNumber = FMC_SDRAM_COLUMN_BITS_NUM_9;
  hsdram1.Init.RowBitsNumber = FMC_SDRAM_ROW_BITS_NUM_12;
  hsdram1.Init.MemoryDataWidth = FMC_SDRAM_MEM_BUS_WIDTH_32;
  hsdram1.Init.InternalBankNumber = FMC_SDRAM_INTERN_BANKS_NUM_4;
  hsdram1.Init.CASLatency = FMC_SDRAM_CAS_LATENCY_3;
  hsdram1.Init.WriteProtection = FMC_SDRAM_WRITE_PROTECTION_DISABLE;
  hsdram1.Init.SDClockPeriod = FMC_SDRAM_CLOCK_PERIOD_2;
  hsdram1.Init.ReadBurst = FMC_SDRAM_RBURST_ENABLE;
  hsdram1.Init.ReadPipeDelay = FMC_SDRAM_RPIPE_DELAY_0;
  /* SdramTiming */
  SdramTiming.LoadToActiveDelay = 2;
  SdramTiming.ExitSelfRefreshDelay = 7;
  SdramTiming.SelfRefreshTime = 4;
  SdramTiming.RowCycleDelay = 7;
  SdramTiming.WriteRecoveryTime = 4;
  SdramTiming.RPDelay = 2;
  SdramTiming.RCDDelay = 2;

  if (HAL_SDRAM_Init(&hsdram1, &SdramTiming) != HAL_OK)
  {
    Error_Handler( );
  }

}

static void MX_GPIO_Init(void)
{
  GPIO_InitTypeDef GPIO_InitStruct = {0};

  /* GPIO Ports Clock Enable */
  __HAL_RCC_GPIOI_CLK_ENABLE();
  __HAL_RCC_GPIOK_CLK_ENABLE();
  __HAL_RCC_GPIOG_CLK_ENABLE();
  __HAL_RCC_GPIOC_CLK_ENABLE();
  __HAL_RCC_GPIOA_CLK_ENABLE();
  __HAL_RCC_GPIOE_CLK_ENABLE();
  __HAL_RCC_GPIOB_CLK_ENABLE();
  __HAL_RCC_GPIOH_CLK_ENABLE();
  __HAL_RCC_GPIOD_CLK_ENABLE();
  __HAL_RCC_GPIOF_CLK_ENABLE();
  __HAL_RCC_GPIOJ_CLK_ENABLE();

  /*Configure GPIO pin Output Level */
  HAL_GPIO_WritePin(AVDD_EN_GPIO_Port, AVDD_EN_Pin, GPIO_PIN_RESET);

  /*Configure GPIO pin Output Level */
  HAL_GPIO_WritePin(RF_RESET_GPIO_Port, RF_RESET_Pin, GPIO_PIN_RESET);

  /*Configure GPIO pin Output Level */
  HAL_GPIO_WritePin(RF_MASTER_READY_GPIO_Port, RF_MASTER_READY_Pin, GPIO_PIN_RESET);

  /*Configure GPIO pin : AVDD_EN_Pin */
  GPIO_InitStruct.Pin = AVDD_EN_Pin;
  GPIO_InitStruct.Mode = GPIO_MODE_OUTPUT_PP;
  GPIO_InitStruct.Pull = GPIO_PULLDOWN;
  GPIO_InitStruct.Speed = GPIO_SPEED_FREQ_LOW;
  HAL_GPIO_Init(AVDD_EN_GPIO_Port, &GPIO_InitStruct);

  /*Configure GPIO pin : RF_RESET_Pin */
  GPIO_InitStruct.Pin = RF_RESET_Pin;
  GPIO_InitStruct.Mode = GPIO_MODE_OUTPUT_OD;
  GPIO_InitStruct.Pull = GPIO_NOPULL;
  GPIO_InitStruct.Speed = GPIO_SPEED_FREQ_LOW;
  HAL_GPIO_Init(RF_RESET_GPIO_Port, &GPIO_InitStruct);

  /*Configure GPIO pin : MICRO_SD_DETECT_Pin */
  GPIO_InitStruct.Pin = MICRO_SD_DETECT_Pin;
  GPIO_InitStruct.Mode = GPIO_MODE_INPUT;
  GPIO_InitStruct.Pull = GPIO_NOPULL;
  HAL_GPIO_Init(MICRO_SD_DETECT_GPIO_Port, &GPIO_InitStruct);

  /*Configure GPIO pins : RF_DIO5_Pin RF_DIO1_Pin */
  GPIO_InitStruct.Pin = RF_DIO5_Pin|RF_DIO1_Pin;
  GPIO_InitStruct.Mode = GPIO_MODE_INPUT;
  GPIO_InitStruct.Pull = GPIO_NOPULL;
  HAL_GPIO_Init(GPIOE, &GPIO_InitStruct);

  /*Configure GPIO pin : RF_DIO0_Pin */
  GPIO_InitStruct.Pin = RF_DIO0_Pin;
  GPIO_InitStruct.Mode = GPIO_MODE_IT_RISING;
  GPIO_InitStruct.Pull = GPIO_NOPULL;
  HAL_GPIO_Init(RF_DIO0_GPIO_Port, &GPIO_InitStruct);

  /*Configure GPIO pin : RF_DIO2_Pin */
  GPIO_InitStruct.Pin = RF_DIO2_Pin;
  GPIO_InitStruct.Mode = GPIO_MODE_INPUT;
  GPIO_InitStruct.Pull = GPIO_NOPULL;
  HAL_GPIO_Init(RF_DIO2_GPIO_Port, &GPIO_InitStruct);

  /*Configure GPIO pin : RF_SLAVE_READY_Pin */
  GPIO_InitStruct.Pin = RF_SLAVE_READY_Pin;
  GPIO_InitStruct.Mode = GPIO_MODE_INPUT;
  GPIO_InitStruct.Pull = GPIO_PULLUP;
  HAL_GPIO_Init(RF_SLAVE_READY_GPIO_Port, &GPIO_InitStruct);

  /*Configure GPIO pin : RF_MASTER_READY_Pin */
  GPIO_InitStruct.Pin = RF_MASTER_READY_Pin;
  GPIO_InitStruct.Mode = GPIO_MODE_OUTPUT_PP;
  GPIO_InitStruct.Pull = GPIO_PULLUP;
  GPIO_InitStruct.Speed = GPIO_SPEED_FREQ_VERY_HIGH;
  HAL_GPIO_Init(RF_MASTER_READY_GPIO_Port, &GPIO_InitStruct);

  /* EXTI interrupt init*/
  HAL_NVIC_SetPriority(EXTI9_5_IRQn, 5, 0);
  HAL_NVIC_EnableIRQ(EXTI9_5_IRQn);

}

__weak void MAIN_taskEntry(void const * argument)
{
  /* init code for FATFS */
  MX_FATFS_Init();

  /* USER CODE BEGIN 5 */
  WG_main();
  /* Infinite loop */
  for(;;)
  {
    osDelay(1);
  }
  /* USER CODE END 5 */
}

/* SYSTEM_montiorCallback function */
__weak void SYSTEM_montiorCallback(void const * argument)
{
}

void HAL_TIM_PeriodElapsedCallback(TIM_HandleTypeDef *htim)
{
  if (htim->Instance == TIM1) {
    HAL_IncTick();
  }
}

void Error_Handler(void)
{
  while(1)
  {
  }
}

/************************ (C) COPYRIGHT STMicroelectronics *****END OF FILE****/

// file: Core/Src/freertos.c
/* USER CODE BEGIN Header */
/**
  ******************************************************************************
  * File Name          : freertos.c
  * Description        : Code for freertos applications
  ******************************************************************************
  * This notice applies to any and all portions of this file
  * that are not between comment pairs USER CODE BEGIN and
  * USER CODE END. Other portions of this file, whether
  * inserted by the user or by software development tools
  * are owned by their respective copyright owners.
  *
  * Copyright (c) 2019 STMicroelectronics International N.V.
  * All rights reserved.
  *
  * Redistribution and use in source and binary forms, with or without
  * modification, are permitted, provided that the following conditions are met:
  *
  * 1. Redistribution of source code must retain the above copyright notice,
  *    this list of conditions and the following disclaimer.
  * 2. Redistributions in binary form must reproduce the above copyright notice,
  *    this list of conditions and the following disclaimer in the documentation
  *    and/or other materials provided with the distribution.
  * 3. Neither the name of STMicroelectronics nor the names of other
  *    contributors to this software may be used to endorse or promote products
  *    derived from this software without specific written permission.
  * 4. This software, including modifications and/or derivative works of this
  *    software, must execute solely and exclusively on microcontroller or
  *    microprocessor devices manufactured by or for STMicroelectronics.
  * 5. Redistribution and use of this software other than as permitted under
  *    this license is void and will automatically terminate your rights under
  *    this license.
  *
  * THIS SOFTWARE IS PROVIDED BY STMICROELECTRONICS AND CONTRIBUTORS "AS IS"
  * AND ANY EXPRESS, IMPLIED OR STATUTORY WARRANTIES, INCLUDING, BUT NOT
  * LIMITED TO, THE IMPLIED WARRANTIES OF MERCHANTABILITY, FITNESS FOR A
  * PARTICULAR PURPOSE AND NON-INFRINGEMENT OF THIRD PARTY INTELLECTUAL PROPERTY
  * RIGHTS ARE DISCLAIMED TO THE FULLEST EXTENT PERMITTED BY LAW. IN NO EVENT
  * SHALL STMICROELECTRONICS OR CONTRIBUTORS BE LIABLE FOR ANY DIRECT, INDIRECT,
  * INCIDENTAL, SPECIAL, EXEMPLARY, OR CONSEQUENTIAL DAMAGES (INCLUDING, BUT NOT
  * LIMITED TO, PROCUREMENT OF SUBSTITUTE GOODS OR SERVICES; LOSS OF USE, DATA,
  * OR PROFITS; OR BUSINESS INTERRUPTION) HOWEVER CAUSED AND ON ANY THEORY OF
  * LIABILITY, WHETHER IN CONTRACT, STRICT LIABILITY, OR TORT (INCLUDING
  * NEGLIGENCE OR OTHERWISE) ARISING IN ANY WAY OUT OF THE USE OF THIS SOFTWARE,
  * EVEN IF ADVISED OF THE POSSIBILITY OF SUCH DAMAGE.
  *
  ******************************************************************************
  */
/* USER CODE END Header */

#include "FreeRTOS.h"
#include "task.h"
#include "main.h"

/* Hook prototypes */
void vApplicationStackOverflowHook(xTaskHandle xTask, signed char *pcTaskName);

/* USER CODE BEGIN 4 */
__weak void vApplicationStackOverflowHook(xTaskHandle xTask, signed char *pcTaskName)
{
   /* Run time stack overflow checking is performed if
   configCHECK_FOR_STACK_OVERFLOW is defined to 1 or 2. This hook function is
   called if a stack overflow is detected. */
}
/* USER CODE END 4 */

/************************ (C) COPYRIGHT STMicroelectronics *****END OF FILE****/
